# NUC505_v1 register map
File version: 1.0
Registers are 32-bit, read-write, reset 0x0 unless marked. A register's access mark holds for its fields unless they carry their own. Offsets are from the block's base; [hi:lo] are bit positions; 'fields as' and 'values as' point back to an identical list.

## SPI0 — SPI Register Map
Base 0x400E9000
Same registers: SPI1 0x400E1000
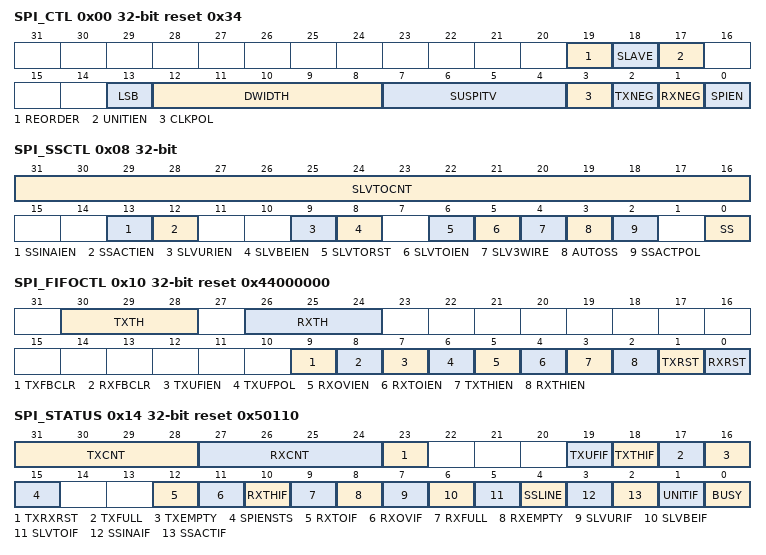
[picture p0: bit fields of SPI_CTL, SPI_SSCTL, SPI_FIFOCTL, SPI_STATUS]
0x00 SPI_CTL reset 0x34 — SPI Control Register
  [19] REORDER — Byte Reorder Function Enable Control. Note: Byte reorder function is only available if DWIDTH is defined as 16, 24, and 32 bits.
    0=Byte reorder function Disabled; 1=Byte reorder function Enabled. A byte suspend interval will be inserted among each byte. The period of the byte suspend interval depends on the setting of SUSPITV (SPI_CTL[7:4])
  [18] SLAVE — Slave Mode Enable Control
    0=Master mode; 1=Slave mode
  [17] UNITIEN — Unit Transfer Interrupt Enable Control
    0=SPI unit transfer interrupt Disabled; 1=SPI unit transfer interrupt Enabled
  [13] LSB — Send LSB First
    0=The MSB, which bit of transmit/receive register depends on the setting of DWIDTH, is transmitted/received first; 1=The LSB, bit 0 of the SPI TX register, is sent first to the SPI data output pin, and the first bit received from the SPI data input pin will be put in the LSB position of the RX register (bit 0 of SPI_RX)
  [12:8] DWIDTH — Data Transmit Bit Width. This field specifies how many bits can be transmitted / received in one transaction. The minimum bit length is 8 bits and can up to 32 bits.
  [7:4] SUSPITV — Suspend Interval (Master Only). The four bits provide configurable suspend interval between two successive transmit/receive transaction in a transfer. The definition of the suspend interval is the interval between the last clock edge of the preceding transaction word and the first clock edge of the following transaction word. The default value is 0x3. The period of the suspend interval is obtained according to the following equation. (SUSPITV[3:0]+0.5) * period of SPICLK clock cycle. Example:
  [3] CLKPOL — Clock Polarity
    0=SPICLK is idle low; 1=SPICLK is idle high
  [2] TXNEG — Transmit on Negative Edge
    0=Transmitted data output signal is changed on the rising edge of SPICLK; 1=Transmitted data output signal is changed on the falling edge of SPICLK
  [1] RXNEG — Receive on Negative Edge
    0=Received data input signal is latched on the rising edge of SPICLK; 1=Received data input signal is latched on the falling edge of SPICLK
  [0] SPIEN — SPI Transfer Control Enable Bit. Note1: In Master mode, the transfer will start when there is data in the FIFO buffer after this is set to 1. In Slave mode, this device is ready to receive data when this bit is set to 1. Note2: The byte reorder function is not supported when the Quad or Dual I/O mode is enabled.
    0=Transfer control bit Disabled; 1=Transfer control bit Enabled
0x04 SPI_CLKDIV — SPI Clock Divider Register
  [7:0] DIVIDER — Clock Divider 1 Register. The value in this field is the frequency divider for generating the SPI engine clock, fspi_eclk, and the SPI serial clock of SPI master. The frequency is obtained according to the following equation. where is the SPI engine clock source, which is defined in the clock control, clock control register.
0x08 SPI_SSCTL — SPI Slave Select Control Register
  [31:16] SLVTOCNT — Slave Mode Time-out Period. In Slave mode, these bits indicate the time-out period when there is serial clock input during slave select active. The clock source of the time-out counter is Slave engine clock. If the value is 0, it indicates the slave mode time-out function is disabled.
  [13] SSINAIEN — Slave Select Inactive Interrupt Enable Control
    0=Slave select inactive interrupt Disable; 1=Slave select inactive interrupt Enable
  [12] SSACTIEN — Slave Select Active Interrupt Enable Control
    0=Slave select active interrupt Disable; 1=Slave select active interrupt Enable
  [9] SLVURIEN — Slave Mode Error 1 Interrupt Enable Control
    0=Slave mode error 1 interrupt Disable; 1=Slave mode error 1 interrupt Enable
  [8] SLVBEIEN — Slave Mode Error 0 Interrupt Enable Control
    0=Slave mode error 0 interrupt Disable; 1=Slave mode error 0 interrupt Enable
  [6] SLVTORST — Slave Mode Time-out FIFO Clear. Note: Both the FIFO clear function, TX_CLK and RXRST, active automatically when there is a slave mode time-out event.
    0=Slave mode Time-out FIFO Clear Disable; 1=Slave mode Time-out FIFO Clear Enable
  [5] SLVTOIEN — Slave Mode Time-out Interrupt Enable Control
    0=Slave mode time-out interrupt Disabled; 1=Slave mode time-out interrupt Enabled
  [4] SLV3WIRE — Slave 3-wire Mode Enable Control. This is used to ignore the slave select signal in Slave mode. The SPI controller can work with 3-wire interface including SPI_CLK, SPI_MISO, and SPI_MOSI.
    0=2-wire bi-direction interface; 1=3-wire bi-direction interface
  [3] AUTOSS — Automatic Slave Select Function Enable (Master Only)
    0=If this bit is cleared, slave select signals will be asserted/de-asserted by setting /clearing the corresponding bit of SPI_SSCTL[0]; 1=If this bit is set, SS signal will be generated automatically. It means that device/slave select signal, which is set in SPI_SSCTL[0], will be asserted by the SPI controller when transmit/receive is started, and will be de-asserted after each transmit/receive is finished
  [2] SSACTPOL — Slave Select Active Level. This bit defines the active status of slave select signal (SS).
    0=The slave select signal SS is active on low-level; 1=The slave select signal SS is active on high-level
  [0] SS — Slave Selection Control (Master Only). If AUTOSS bit is cleared to 0,
    0=set the SPIn_SS line to inactive state. Keep the SPIn_SS line at inactive state; 1=set the SPIn_SS line to active state. SPIn_SS line will be automatically driven to active state for the duration of data transfer, and will be driven to inactive state for the rest of the time. The active state of SPIn_SS is specified in SSACTPOL (SPI_SSCTL[2])
0x10 SPI_FIFOCTL reset 0x44000000 — SPI FIFO Control Register
  [30:28] TXTH — Transmit FIFO Threshold. If the valid data count of the transmit FIFO buffer is less than or equal to the TXTH setting, the TXTHIF (SPI_STATUS[18]) will be set to 1, else the TXTHIF (SPI_STATUS[18]) will be cleared to 0.
  [26:24] RXTH — Receive FIFO Threshold. If the valid data count of the receive FIFO buffer is larger than the RXTH setting, the RXTHIF (SPI_STATUS[10]) will be set to 1, else the RXTHIF (SPI_STATUS[10]) will be cleared to 0.
  [9] TXFBCLR — Clear Transmit FIFO. Note: Auto cleared by Hardware.
    0=No effect; 1=Clear transmit FIFO only
  [8] RXFBCLR — Clear Receive FIFO. Note: Auto cleared by Hardware.
    0=No effect; 1=Clear receive FIFO only
  [7] TXUFIEN — Slave Transmit Under Run Interrupt Enable Control
    0=Slave Transmit FIFO under-run interrupt Disabled; 1=Slave Transmit FIFO under-run interrupt Enabled
  [6] TXUFPOL — Transmit Under-run Data Out. Note1: The under run event is active after the serial clock input and the hardware synchronous, so that the first 1~3 bit (depending on the relation between system clock and the engine clock) data out will be the last transaction data. Note2: If the frequency of system clock approach to engine clock, they may need 3-bit time to report the transmit under-run data out.
    0=The SPI data out is keep 0 if there is transmit under-run event in Slave mode; 1=The SPI data out is keep 1 if there is transmit under-run event in Slave mode
  [5] RXOVIEN — Receive FIFO Overrun Interrupt Enable Control
    0=Receive FIFO overrun interrupt Disabled; 1=Receive FIFO overrun interrupt Enabled
  [4] RXTOIEN — Slave Receive Time-out Interrupt Enable Control
    0=Receive time-out interrupt Disabled; 1=Receive time-out interrupt Enabled
  [3] TXTHIEN — Transmit FIFO Threshold Interrupt Enable Control
    0=TX FIFO threshold interrupt Disabled; 1=TX FIFO threshold interrupt Enabled
  [2] RXTHIEN — Receive FIFO Threshold Interrupt Enable Control
    0=RX FIFO threshold interrupt Disabled; 1=RX FIFO threshold interrupt Enabled
  [1] TXRST — Clear Transmit FIFO Control. Note: If there is slave receive time-out event, the TXRST will be set 1 when the SLVTORST (SPI_SSCTL[6]) is enabled.
    0=No effect; 1=Clear transmit FIFO control. The TXFULL (SPI_STATUS[17]) will be cleared to 0 and the TXEMPTY (SPI_STATUS[16]) will be set to 1. This bit will be cleared to 0 by hardware about 3 system clocks+3 SPI engine clock after it is set to 1
  [0] RXRST — Clear Receive FIFO Control. Note: If there is slave receive time-out event, the RXRST will be set 1 when the SLVTORST (SPI_SSCTL[6]) is enabled.
    0=No effect; 1=Clear receive FIFO control. The RXFULL (SPI_STATUS[9]) will be cleared to 0 and the RXEMPTY (SPI_STATUS[8]) will be set to 1. This bit will be cleared to 0 by hardware about 3 system clocks+3 SPI engine clock after it is set to 1
0x14 SPI_STATUS reset 0x50110
  [31:28] TXCNT ro — Transmit FIFO Data Count (Read Only). This bit field indicates the valid data count of transmit FIFO buffer.
  [27:24] RXCNT ro — Receive FIFO Data Count (Read Only). This bit field indicates the valid data count of receive FIFO buffer.
  [23] TXRXRST ro — FIFO CLR Status (Read Only). Note: Both the TXRST (SPI_FIFOCTL[1]), RXRST (SPI_FIFOCTL[0]), need 3 system clock+3 engine clock , the status of this bit support the user to monitor the clear function is doing or done.
    0=Done the FIFO buffer clear function of TXRST (SPI_FIFOCTL[1]) or RXRST (SPI_FIFOCTL[0]); 1=Doing the FIFO buffer clear function of TXRST (SPI_FIFOCTL[1])or RXRST (SPI_FIFOCTL[0])
  [19] TXUFIF — TX Underflow Interrupt Flag. When the TX underflow event occurs, this bit will be set to 1, the state of data output pin depends on the setting of TXUFPOL. Note 1: This bit will be cleared by writing 1 to it. Note 2: If reset slave's transmission circuit when slave selection signal is active, this flag will be set to 1 after 3 system clock cycles + 2 peripheral clock cycles since the reset operation is done.
    0=No effect; 1=No data in Transmit FIFO and TX shift register when the slave selection signal is active
  [18] TXTHIF ro — Transmit FIFO Threshold Interrupt Status (Read Only)
    0=The valid data count within the transmit FIFO buffer is larger than the setting value of TXTH (SPI_FIFOCTL[30:28]); 1=The valid data count within the transmit FIFO buffer is less than or equal to the setting value of TXTH (SPI_FIFOCTL[30:28])
  [17] TXFULL ro — Transmit FIFO Buffer Full Indicator (Read Only)
    0=Transmit FIFO buffer is not full; 1=Transmit FIFO buffer is full
  [16] TXEMPTY ro — Transmit FIFO Buffer Empty Indicator (Read Only)
    0=Transmit FIFO buffer is not empty; 1=Transmit FIFO buffer is empty
  [15] SPIENSTS ro — SPI Enable Bit Status (Read Only). The clock source of SPI controller logic is engine clock, it is asynchronous with the system clock. In order to make sure the function is disabled in SPI controller logic, this bit indicates the real status of SPIEN (SPI_CTL[0]) in SPI controller logic for user.
    0=Indicate the transmit control bit is disabled; 1=Indicate the transfer control bit is active
  [12] RXTOIF — Receive Time-out Interrupt Status. Note: This bit will be cleared by writing 1 to itself.
    0=No receive FIFO time-out event; 1=Receive FIFO buffer is not empty and no read operation on receive FIFO buffer over 64 SPI clock period in Master mode or over 576 SPI engine clock period in Slave mode. When the received FIFO buffer is read by software, the time-out status will be cleared automatically
  [11] RXOVIF — Receive FIFO Overrun Status. Note: This bit will be cleared by writing 1 to itself.
    0=No receiver FIFO overrun status; 1=Receive FIFO buffer is full, the follow-up data will be dropped and this bit will be set to 1
  [10] RXTHIF ro — Receive FIFO Threshold Interrupt Status (Read Only)
    0=The valid data count within the RX FIFO buffer is smaller than or equal to the setting value of RXTH (SPI_FIFOCTL[26:24]); 1=The valid data count within the receive FIFO buffer is larger than the setting value of RXTH (SPI_FIFOCTL[26:24])
  [9] RXFULL ro — Receive FIFO Buffer Empty Indicator (Read Only)
    0=Receive FIFO buffer is not empty; 1=Receive FIFO buffer is empty
  [8] RXEMPTY ro — Receive FIFO Buffer Empty Indicator (Read Only)
    values as RXFULL
  [7] SLVURIF ro — Slave Mode Error 1 Interrupt Status (Read Only). In Slave mode, transmit under-run occurs when the slave select line goes to inactive state.
    0=No Slave mode error 1 event; 1=Slave mode error 1 occurs
  [6] SLVBEIF ro — Slave Mode Error 0 Interrupt Status (Read Only). In Slave mode, there is bit counter mismatch with DWIDTH (SPI_CTL[12:8]) when the slave select line goes to inactive state. Note: If the slave select active but there is no any serial clock input, the SLVBEIF (SPI_STATUS[6]) also active when the slave select goes to inactive state.
    0=No Slave mode error 0 event; 1=Slave mode error 0 occurs
  [5] SLVTOIF ro — Slave Time-out Interrupt Status (Read Only). When the Slave Select is active and the value of SLVTOCNT (SPI_SSCTL[31:16]) is not 0 and the serial clock input, the slave time-out counter in SPI controller logic will be start. When the value of time-out counter greater or equal than the value of SLVTOCNT (SPI_SSCTL[31:16]) during before one transaction done, the slave time-out interrupt event will active. Note: If the DWIDTH (SPI_CTL[12:8]) is set 0x10, one transaction is equal 16 bits serial clock period.
    0=Slave time-out is not active; 1=Slave time-out is active
  [4] SSLINE ro — Slave Select Line Bus Status (Read Only). Note: If SSACTPOL (SPI_SSCTL[2]) is set 0, and the SSLINE is 1, the SPI slave select is in inactive status.
    0=Indicates the slave select line bus status is 0; 1=Indicates the slave select line bus status is 1
  [3] SSINAIF — Slave Select Inactive Interrupt Status. Note: This bit will be cleared by writing 1 to itself.
    0=Slave select inactive interrupt is cleared or did not occur; 1=Slave select inactive interrupt event has occurred
  [2] SSACTIF — Slave Select Active Interrupt Status. Note: This bit will be cleared by writing 1 to itself.
    0=Slave select active interrupt is cleared or did not occur; 1=Slave select active interrupt event has occurred
  [1] UNITIF — Unit Transfer Interrupt Status. Note: This bit will be cleared by writing 1 to itself.
    0=No transaction has been finished since this bit was cleared to 0; 1=SPI controller has finished one unit transfer
  [0] BUSY ro — SPI Unit Bus Status (Read Only)
    0=No transaction in the SPI bus; 1=SPI controller unit in busy state
0x20 SPI_TX wo — SPI Data Transmit Register
  [31:0] TX — Data Transmit Register. The data transmit registers pass through the transmitted data into the 8-level transmit FIFO buffer. The number of valid bits depends on the setting of transmit bit width field of the SPI_CTL register. For example, if DWIDTH (SPI_CTL[12:8]) is set to 0x08, the bits TX[7:0] will be transmitted. If DWIDTH (SPI_CTL[12:8]) is set to 0x00, the SPI controller will perform a 32-bit transfer.
0x30 SPI_RX ro — SPI Data Receive Register
  [31:0] RX — Data Receive Register. There is 8-level FIFO buffer in this controller. The data receive register holds the earliest datum received from SPI data input pin. If the RXEMPTY (SPI_STATUS[8]) is not set to 1, the receive FIFO buffer can be accessed through software by reading this register. This is a read-only register.
